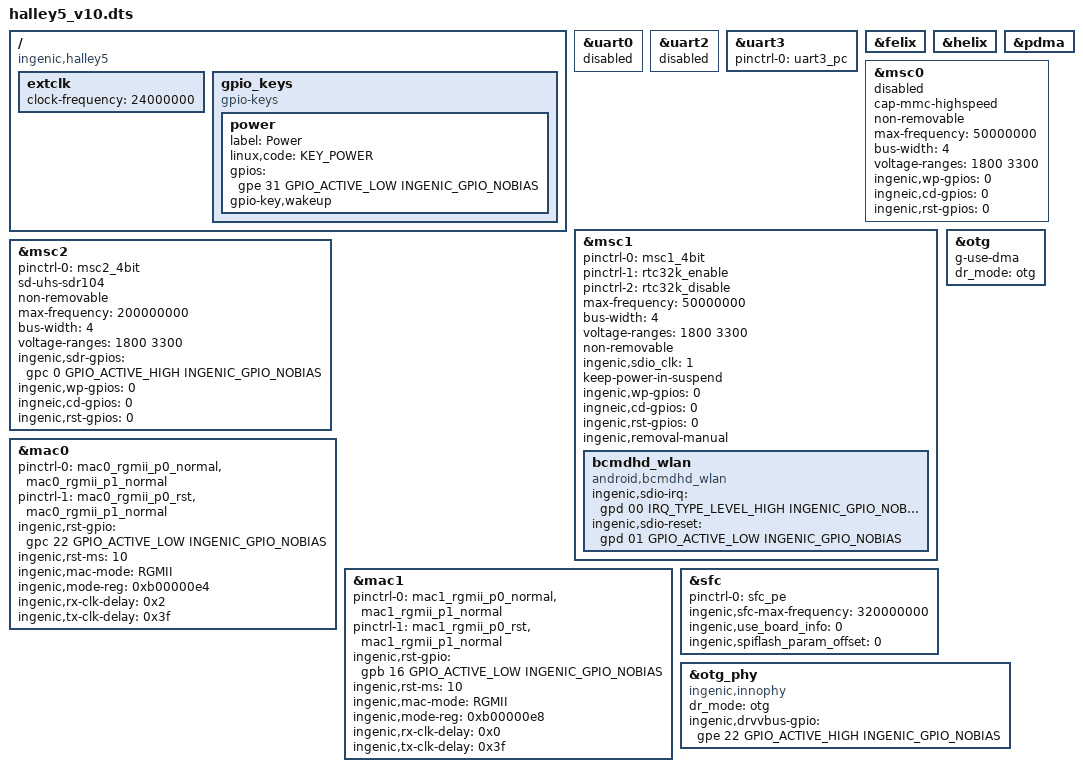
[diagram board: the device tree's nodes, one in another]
/dts-v1/;

#include <dt-bindings/input/input.h>
#include "x2000-v12.dtsi"
#include <dt-bindings/interrupt-controller/irq.h>

/ {
	compatible = "ingenic,halley5", "ingenic,x2000-v12";
};

&uart0 {
	status = "disable";
};

&uart2 {
	status = "disable";
};

&uart3 {
	status = "okay";
	pinctrl-names = "default";
	pinctrl-0 = <&uart3_pc>;
};

&felix {
	status = "okay";
};

&helix {
	status = "okay";
};

&pdma {
	status = "okay";
};

&msc0 {
	status = "disable";
	/*mmc-hs200-1_8v;*/
	cap-mmc-highspeed;
	non-removable;
	max-frequency = <50000000>;
	bus-width = <4>;
	non-removable;
	voltage-ranges = <1800 3300>;

	/* special property */
	ingenic,wp-gpios = <0>;
	ingneic,cd-gpios = <0>;
	ingenic,rst-gpios = <0>;
};

&msc1 {
	status = "okay";
	pinctrl-names ="default","enable", "disable";
	pinctrl-0 = <&msc1_4bit>;
	pinctrl-1 = <&rtc32k_enable>;
	pinctrl-2 = <&rtc32k_disable>;

	max-frequency = <50000000>;
	bus-width = <4>;
	voltage-ranges = <1800 3300>;
	non-removable;

	ingenic,sdio_clk = <1>;
	keep-power-in-suspend;

	/* special property */
	ingenic,wp-gpios = <0>;
	ingneic,cd-gpios = <0>;
	ingenic,rst-gpios = <0>;
	ingenic,removal-manual; /*removal-dontcare, removal-nonremovable, removal-removable, removal-manual*/

	bcmdhd_wlan: bcmdhd_wlan {
		 compatible = "android,bcmdhd_wlan";
		 ingenic,sdio-irq = <&gpd 00 IRQ_TYPE_LEVEL_HIGH INGENIC_GPIO_NOBIAS>;
		 ingenic,sdio-reset = <&gpd 01 GPIO_ACTIVE_LOW INGENIC_GPIO_NOBIAS>;
	};
};

&msc2 {
	status = "okay";
	pinctrl-names ="default";
	pinctrl-0 = <&msc2_4bit>;
	sd-uhs-sdr104;
	/*cap-mmc-highspeed;*/
	non-removable;
	max-frequency = <200000000>;
	bus-width = <4>;
	non-removable;
	voltage-ranges = <1800 3300>;

	/* special property */
	ingenic,sdr-gpios = <&gpc 0 GPIO_ACTIVE_HIGH INGENIC_GPIO_NOBIAS>;
	ingenic,wp-gpios = <0>;
	ingneic,cd-gpios = <0>;
	ingenic,rst-gpios = <0>;
};

&mac0 {
	pinctrl-names = "default", "reset";
	pinctrl-0 = <&mac0_rgmii_p0_normal>, <&mac0_rgmii_p1_normal>;
	pinctrl-1 = <&mac0_rgmii_p0_rst>, <&mac0_rgmii_p1_normal>;
	status = "okay";
	ingenic,rst-gpio = <&gpc 22 GPIO_ACTIVE_LOW INGENIC_GPIO_NOBIAS>;
	ingenic,rst-ms = <10>;
	ingenic,mac-mode = <RGMII>;
	ingenic,mode-reg = <0xb00000e4>;
	ingenic,rx-clk-delay = <0x2>;
	ingenic,tx-clk-delay = <0x3f>;
};

&mac1 {
	pinctrl-names = "default", "reset";
	pinctrl-0 = <&mac1_rgmii_p0_normal>, <&mac1_rgmii_p1_normal>;
	pinctrl-1 = <&mac1_rgmii_p0_rst>, <&mac1_rgmii_p1_normal>;
	status = "okay";
	ingenic,rst-gpio = <&gpb 16 GPIO_ACTIVE_LOW INGENIC_GPIO_NOBIAS>;
	ingenic,rst-ms = <10>;
	ingenic,mac-mode = <RGMII>;
	ingenic,mode-reg = <0xb00000e8>;
	ingenic,rx-clk-delay = <0x0>;
	ingenic,tx-clk-delay = <0x3f>;
};

&sfc {
	status = "okay";
	pinctrl-names = "default";
	pinctrl-0 = <&sfc_pe>;
	ingenic,sfc-max-frequency = <320000000>;
	ingenic,use_board_info      = /bits/ 8 <0>;
	ingenic,spiflash_param_offset = <0>;
};

&otg {
	g-use-dma;
	dr_mode = "otg";
	status = "okay";
};


&otg_phy {
	dr_mode = "otg";
	compatible = "ingenic,innophy", "syscon";
	ingenic,drvvbus-gpio = <&gpe 22 GPIO_ACTIVE_HIGH INGENIC_GPIO_NOBIAS>;
	status = "okay";
};



/ {

	extclk: extclk {
		clock-frequency = <24000000>;
	};

	gpio_keys: gpio_keys {
		   compatible = "gpio-keys";

		   power {
			   label = "Power";
			   linux,code = <KEY_POWER>;
			   gpios = <&gpe 31 GPIO_ACTIVE_LOW INGENIC_GPIO_NOBIAS>;
			   gpio-key,wakeup;
		   };
	   };

};
